[part 1 of 3: package /MICROSAR_SWCS_DEV/Dem_swc/ComponentTypes]
AUTOSAR XML (schema 4-0-3)
package /MICROSAR_SWCS_DEV/Dem_swc/ComponentTypes
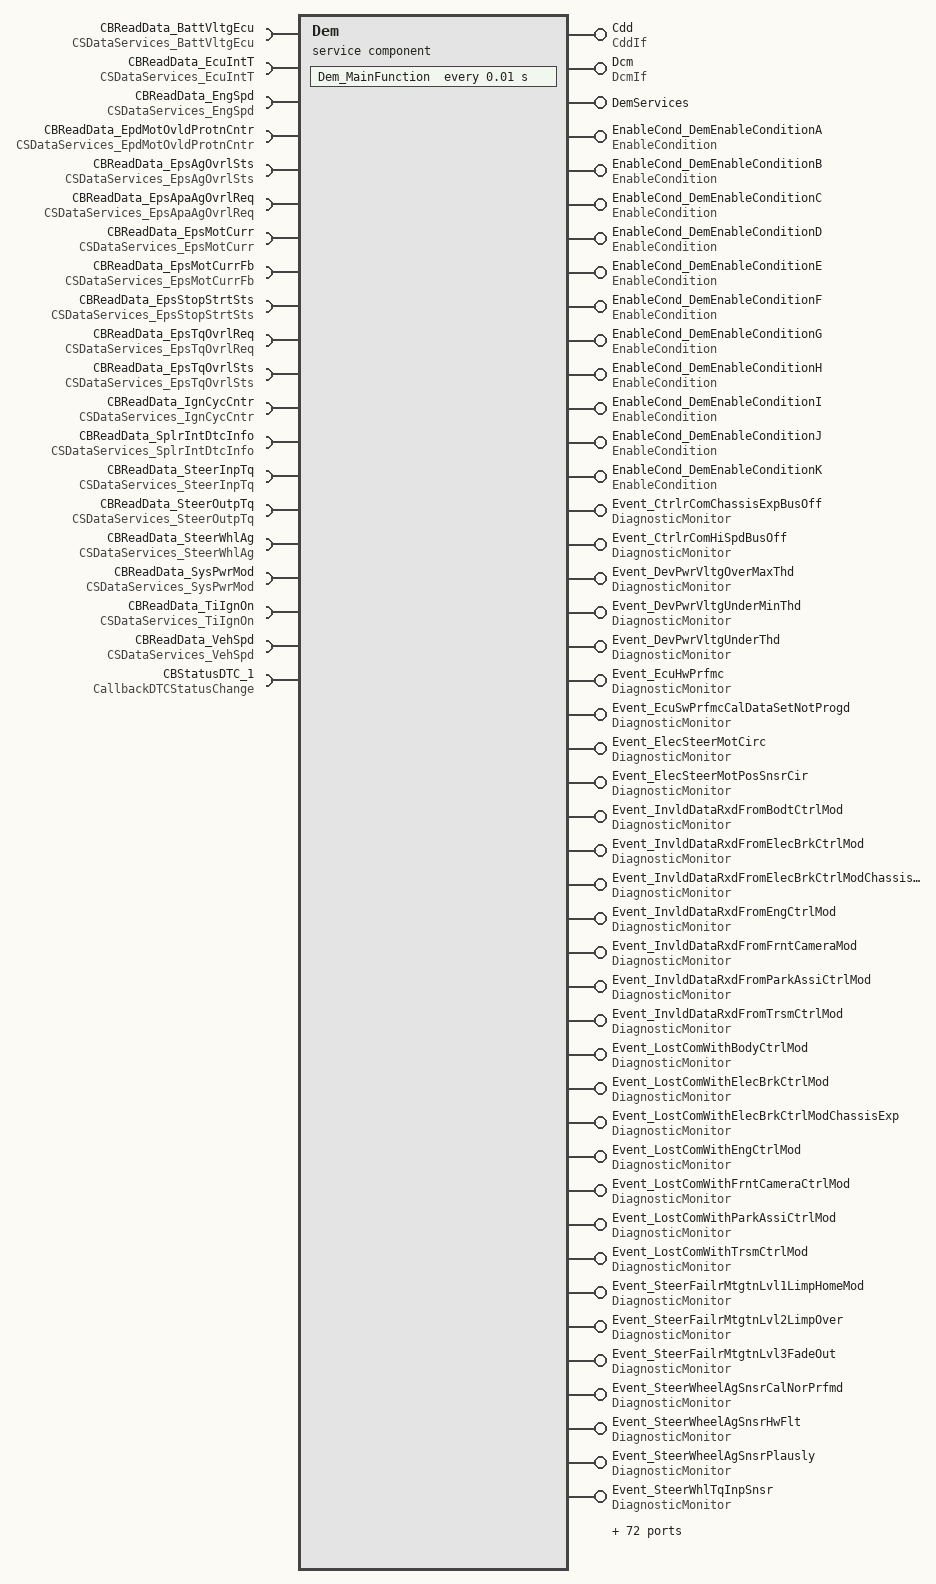
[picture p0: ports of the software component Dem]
  service sw component type Dem
    116 x provide port:
      Cdd: server-com-spec{operation=ClearDTC, queue-length=1}, provided-interface=CddIf
      Dcm: provided-interface=DcmIf
        provided-com-specs:
          operation=DcmClearDTC, queue-length=1
          operation=DcmEnableDTCSetting, queue-length=1
          operation=DcmGetExtendedDataRecordByDTC, queue-length=1
          operation=DcmGetFreezeFrameDataByDTC, queue-length=1
          operation=DcmGetNextFilteredDTCAndFDC, queue-length=1
      DemServices: provided-interface=DemServices
        provided-com-specs:
          operation=GetDTCStatusAvailabilityMask, queue-length=1
          operation=GetPostRunRequested, queue-length=1
      EnableCond_DemEnableConditionA: server-com-spec{operation=SetEnableCondition, queue-length=1}, provided-interface=EnableCondition
      EnableCond_DemEnableConditionB: server-com-spec{operation=SetEnableCondition, queue-length=1}, provided-interface=EnableCondition
      EnableCond_DemEnableConditionC: server-com-spec{operation=SetEnableCondition, queue-length=1}, provided-interface=EnableCondition
      EnableCond_DemEnableConditionD: server-com-spec{operation=SetEnableCondition, queue-length=1}, provided-interface=EnableCondition
      EnableCond_DemEnableConditionE: server-com-spec{operation=SetEnableCondition, queue-length=1}, provided-interface=EnableCondition
      EnableCond_DemEnableConditionF: server-com-spec{operation=SetEnableCondition, queue-length=1}, provided-interface=EnableCondition
      EnableCond_DemEnableConditionG: server-com-spec{operation=SetEnableCondition, queue-length=1}, provided-interface=EnableCondition
      EnableCond_DemEnableConditionH: server-com-spec{operation=SetEnableCondition, queue-length=1}, provided-interface=EnableCondition
      EnableCond_DemEnableConditionI: server-com-spec{operation=SetEnableCondition, queue-length=1}, provided-interface=EnableCondition
      EnableCond_DemEnableConditionJ: server-com-spec{operation=SetEnableCondition, queue-length=1}, provided-interface=EnableCondition
      EnableCond_DemEnableConditionK: server-com-spec{operation=SetEnableCondition, queue-length=1}, provided-interface=EnableCondition
      Event_CtrlrComChassisExpBusOff: provided-interface=DiagnosticMonitor
        provided-com-specs:
          operation=GetDTCOfEvent, queue-length=1
          operation=GetEventExtendedDataRecord, queue-length=1
          operation=GetEventFailed, queue-length=1
          operation=GetEventFreezeFrameData, queue-length=1
          operation=GetEventStatus, queue-length=1
          operation=GetEventTested, queue-length=1
          operation=GetFaultDetectionCounter, queue-length=1
          operation=ResetEventDebounceStatus, queue-length=1
          operation=ResetEventStatus, queue-length=1
          operation=SetEventStatus, queue-length=1
      Event_CtrlrComHiSpdBusOff: provided-interface=DiagnosticMonitor
        provided-com-specs:
          operation=GetDTCOfEvent, queue-length=1
          operation=GetEventExtendedDataRecord, queue-length=1
          operation=GetEventFailed, queue-length=1
          operation=GetEventFreezeFrameData, queue-length=1
          operation=GetEventStatus, queue-length=1
          operation=GetEventTested, queue-length=1
          operation=GetFaultDetectionCounter, queue-length=1
          operation=ResetEventDebounceStatus, queue-length=1
          operation=ResetEventStatus, queue-length=1
          operation=SetEventStatus, queue-length=1
      Event_DevPwrVltgOverMaxThd: provided-interface=DiagnosticMonitor
        provided-com-specs:
          operation=GetDTCOfEvent, queue-length=1
          operation=GetEventExtendedDataRecord, queue-length=1
          operation=GetEventFailed, queue-length=1
          operation=GetEventFreezeFrameData, queue-length=1
          operation=GetEventStatus, queue-length=1
          operation=GetEventTested, queue-length=1
          operation=GetFaultDetectionCounter, queue-length=1
          operation=ResetEventDebounceStatus, queue-length=1
          operation=ResetEventStatus, queue-length=1
          operation=SetEventStatus, queue-length=1
      Event_DevPwrVltgUnderMinThd: provided-interface=DiagnosticMonitor
        provided-com-specs:
          operation=GetDTCOfEvent, queue-length=1
          operation=GetEventExtendedDataRecord, queue-length=1
          operation=GetEventFailed, queue-length=1
          operation=GetEventFreezeFrameData, queue-length=1
          operation=GetEventStatus, queue-length=1
          operation=GetEventTested, queue-length=1
          operation=GetFaultDetectionCounter, queue-length=1
          operation=ResetEventDebounceStatus, queue-length=1
          operation=ResetEventStatus, queue-length=1
          operation=SetEventStatus, queue-length=1
      Event_DevPwrVltgUnderThd: provided-interface=DiagnosticMonitor
        provided-com-specs:
          operation=GetDTCOfEvent, queue-length=1
          operation=GetEventExtendedDataRecord, queue-length=1
          operation=GetEventFailed, queue-length=1
          operation=GetEventFreezeFrameData, queue-length=1
          operation=GetEventStatus, queue-length=1
          operation=GetEventTested, queue-length=1
          operation=GetFaultDetectionCounter, queue-length=1
          operation=ResetEventDebounceStatus, queue-length=1
          operation=ResetEventStatus, queue-length=1
          operation=SetEventStatus, queue-length=1
      Event_EcuHwPrfmc: provided-interface=DiagnosticMonitor
        provided-com-specs:
          operation=GetDTCOfEvent, queue-length=1
          operation=GetEventExtendedDataRecord, queue-length=1
          operation=GetEventFailed, queue-length=1
          operation=GetEventFreezeFrameData, queue-length=1
          operation=GetEventStatus, queue-length=1
          operation=GetEventTested, queue-length=1
          operation=GetFaultDetectionCounter, queue-length=1
          operation=ResetEventDebounceStatus, queue-length=1
          operation=ResetEventStatus, queue-length=1
          operation=SetEventStatus, queue-length=1
      Event_EcuSwPrfmcCalDataSetNotProgd: provided-interface=DiagnosticMonitor
        provided-com-specs:
          operation=GetDTCOfEvent, queue-length=1
          operation=GetEventExtendedDataRecord, queue-length=1
          operation=GetEventFailed, queue-length=1
          operation=GetEventFreezeFrameData, queue-length=1
          operation=GetEventStatus, queue-length=1
          operation=GetEventTested, queue-length=1
          operation=GetFaultDetectionCounter, queue-length=1
          operation=ResetEventDebounceStatus, queue-length=1
          operation=ResetEventStatus, queue-length=1
          operation=SetEventStatus, queue-length=1
      Event_ElecSteerMotCirc: provided-interface=DiagnosticMonitor
        provided-com-specs:
          operation=GetDTCOfEvent, queue-length=1
          operation=GetEventExtendedDataRecord, queue-length=1
          operation=GetEventFailed, queue-length=1
          operation=GetEventFreezeFrameData, queue-length=1
          operation=GetEventStatus, queue-length=1
          operation=GetEventTested, queue-length=1
          operation=GetFaultDetectionCounter, queue-length=1
          operation=ResetEventDebounceStatus, queue-length=1
          operation=ResetEventStatus, queue-length=1
          operation=SetEventStatus, queue-length=1
      Event_ElecSteerMotPosSnsrCir: provided-interface=DiagnosticMonitor
        provided-com-specs:
          operation=GetDTCOfEvent, queue-length=1
          operation=GetEventExtendedDataRecord, queue-length=1
          operation=GetEventFailed, queue-length=1
          operation=GetEventFreezeFrameData, queue-length=1
          operation=GetEventStatus, queue-length=1
          operation=GetEventTested, queue-length=1
          operation=GetFaultDetectionCounter, queue-length=1
          operation=ResetEventDebounceStatus, queue-length=1
          operation=ResetEventStatus, queue-length=1
          operation=SetEventStatus, queue-length=1
      Event_InvldDataRxdFromBodtCtrlMod: provided-interface=DiagnosticMonitor
        provided-com-specs:
          operation=GetDTCOfEvent, queue-length=1
          operation=GetEventExtendedDataRecord, queue-length=1
          operation=GetEventFailed, queue-length=1
          operation=GetEventFreezeFrameData, queue-length=1
          operation=GetEventStatus, queue-length=1
          operation=GetEventTested, queue-length=1
          operation=GetFaultDetectionCounter, queue-length=1
          operation=ResetEventDebounceStatus, queue-length=1
          operation=ResetEventStatus, queue-length=1
          operation=SetEventStatus, queue-length=1
      Event_InvldDataRxdFromElecBrkCtrlMod: provided-interface=DiagnosticMonitor
        provided-com-specs:
          operation=GetDTCOfEvent, queue-length=1
          operation=GetEventExtendedDataRecord, queue-length=1
          operation=GetEventFailed, queue-length=1
          operation=GetEventFreezeFrameData, queue-length=1
          operation=GetEventStatus, queue-length=1
          operation=GetEventTested, queue-length=1
          operation=GetFaultDetectionCounter, queue-length=1
          operation=ResetEventDebounceStatus, queue-length=1
          operation=ResetEventStatus, queue-length=1
          operation=SetEventStatus, queue-length=1
      Event_InvldDataRxdFromElecBrkCtrlModChassisExp: provided-interface=DiagnosticMonitor
        provided-com-specs:
          operation=GetDTCOfEvent, queue-length=1
          operation=GetEventExtendedDataRecord, queue-length=1
          operation=GetEventFailed, queue-length=1
          operation=GetEventFreezeFrameData, queue-length=1
          operation=GetEventStatus, queue-length=1
          operation=GetEventTested, queue-length=1
          operation=GetFaultDetectionCounter, queue-length=1
          operation=ResetEventDebounceStatus, queue-length=1
          operation=ResetEventStatus, queue-length=1
          operation=SetEventStatus, queue-length=1
      Event_InvldDataRxdFromEngCtrlMod: provided-interface=DiagnosticMonitor
        provided-com-specs:
          operation=GetDTCOfEvent, queue-length=1
          operation=GetEventExtendedDataRecord, queue-length=1
          operation=GetEventFailed, queue-length=1
          operation=GetEventFreezeFrameData, queue-length=1
          operation=GetEventStatus, queue-length=1
          operation=GetEventTested, queue-length=1
          operation=GetFaultDetectionCounter, queue-length=1
          operation=ResetEventDebounceStatus, queue-length=1
          operation=ResetEventStatus, queue-length=1
          operation=SetEventStatus, queue-length=1
      Event_InvldDataRxdFromFrntCameraMod: provided-interface=DiagnosticMonitor
        provided-com-specs:
          operation=GetDTCOfEvent, queue-length=1
          operation=GetEventExtendedDataRecord, queue-length=1
          operation=GetEventFailed, queue-length=1
          operation=GetEventFreezeFrameData, queue-length=1
          operation=GetEventStatus, queue-length=1
          operation=GetEventTested, queue-length=1
          operation=GetFaultDetectionCounter, queue-length=1
          operation=ResetEventDebounceStatus, queue-length=1
          operation=ResetEventStatus, queue-length=1
          operation=SetEventStatus, queue-length=1
      Event_InvldDataRxdFromParkAssiCtrlMod: provided-interface=DiagnosticMonitor
        provided-com-specs:
          operation=GetDTCOfEvent, queue-length=1
          operation=GetEventExtendedDataRecord, queue-length=1
          operation=GetEventFailed, queue-length=1
          operation=GetEventFreezeFrameData, queue-length=1
          operation=GetEventStatus, queue-length=1
          operation=GetEventTested, queue-length=1
          operation=GetFaultDetectionCounter, queue-length=1
          operation=ResetEventDebounceStatus, queue-length=1
          operation=ResetEventStatus, queue-length=1
          operation=SetEventStatus, queue-length=1
      Event_InvldDataRxdFromTrsmCtrlMod: provided-interface=DiagnosticMonitor
        provided-com-specs:
          operation=GetDTCOfEvent, queue-length=1
          operation=GetEventExtendedDataRecord, queue-length=1
          operation=GetEventFailed, queue-length=1
          operation=GetEventFreezeFrameData, queue-length=1
          operation=GetEventStatus, queue-length=1
          operation=GetEventTested, queue-length=1
          operation=GetFaultDetectionCounter, queue-length=1
          operation=ResetEventDebounceStatus, queue-length=1
          operation=ResetEventStatus, queue-length=1
          operation=SetEventStatus, queue-length=1
      Event_LostComWithBodyCtrlMod: provided-interface=DiagnosticMonitor
        provided-com-specs:
          operation=GetDTCOfEvent, queue-length=1
          operation=GetEventExtendedDataRecord, queue-length=1
          operation=GetEventFailed, queue-length=1
          operation=GetEventFreezeFrameData, queue-length=1
          operation=GetEventStatus, queue-length=1
          operation=GetEventTested, queue-length=1
          operation=GetFaultDetectionCounter, queue-length=1
          operation=ResetEventDebounceStatus, queue-length=1
          operation=ResetEventStatus, queue-length=1
          operation=SetEventStatus, queue-length=1
      Event_LostComWithElecBrkCtrlMod: provided-interface=DiagnosticMonitor
        provided-com-specs:
          operation=GetDTCOfEvent, queue-length=1
          operation=GetEventExtendedDataRecord, queue-length=1
          operation=GetEventFailed, queue-length=1
          operation=GetEventFreezeFrameData, queue-length=1
          operation=GetEventStatus, queue-length=1
          operation=GetEventTested, queue-length=1
          operation=GetFaultDetectionCounter, queue-length=1
          operation=ResetEventDebounceStatus, queue-length=1
          operation=ResetEventStatus, queue-length=1
          operation=SetEventStatus, queue-length=1
      Event_LostComWithElecBrkCtrlModChassisExp: provided-interface=DiagnosticMonitor
        provided-com-specs:
          operation=GetDTCOfEvent, queue-length=1
          operation=GetEventExtendedDataRecord, queue-length=1
          operation=GetEventFailed, queue-length=1
          operation=GetEventFreezeFrameData, queue-length=1
          operation=GetEventStatus, queue-length=1
          operation=GetEventTested, queue-length=1
          operation=GetFaultDetectionCounter, queue-length=1
          operation=ResetEventDebounceStatus, queue-length=1
          operation=ResetEventStatus, queue-length=1
          operation=SetEventStatus, queue-length=1
      Event_LostComWithEngCtrlMod: provided-interface=DiagnosticMonitor
        provided-com-specs:
          operation=GetDTCOfEvent, queue-length=1
          operation=GetEventExtendedDataRecord, queue-length=1
          operation=GetEventFailed, queue-length=1
          operation=GetEventFreezeFrameData, queue-length=1
          operation=GetEventStatus, queue-length=1
          operation=GetEventTested, queue-length=1
          operation=GetFaultDetectionCounter, queue-length=1
          operation=ResetEventDebounceStatus, queue-length=1
          operation=ResetEventStatus, queue-length=1
          operation=SetEventStatus, queue-length=1
      Event_LostComWithFrntCameraCtrlMod: provided-interface=DiagnosticMonitor
        provided-com-specs:
          operation=GetDTCOfEvent, queue-length=1
          operation=GetEventExtendedDataRecord, queue-length=1
          operation=GetEventFailed, queue-length=1
          operation=GetEventFreezeFrameData, queue-length=1
          operation=GetEventStatus, queue-length=1
          operation=GetEventTested, queue-length=1
          operation=GetFaultDetectionCounter, queue-length=1
          operation=ResetEventDebounceStatus, queue-length=1
          operation=ResetEventStatus, queue-length=1
          operation=SetEventStatus, queue-length=1
      Event_LostComWithParkAssiCtrlMod: provided-interface=DiagnosticMonitor
        provided-com-specs:
          operation=GetDTCOfEvent, queue-length=1
          operation=GetEventExtendedDataRecord, queue-length=1
          operation=GetEventFailed, queue-length=1
          operation=GetEventFreezeFrameData, queue-length=1
          operation=GetEventStatus, queue-length=1
          operation=GetEventTested, queue-length=1
          operation=GetFaultDetectionCounter, queue-length=1
          operation=ResetEventDebounceStatus, queue-length=1
          operation=ResetEventStatus, queue-length=1
          operation=SetEventStatus, queue-length=1
      Event_LostComWithTrsmCtrlMod: provided-interface=DiagnosticMonitor
        provided-com-specs:
          operation=GetDTCOfEvent, queue-length=1
          operation=GetEventExtendedDataRecord, queue-length=1
          operation=GetEventFailed, queue-length=1
          operation=GetEventFreezeFrameData, queue-length=1
          operation=GetEventStatus, queue-length=1
          operation=GetEventTested, queue-length=1
          operation=GetFaultDetectionCounter, queue-length=1
          operation=ResetEventDebounceStatus, queue-length=1
          operation=ResetEventStatus, queue-length=1
          operation=SetEventStatus, queue-length=1
      Event_SteerFailrMtgtnLvl1LimpHomeMod: provided-interface=DiagnosticMonitor
        provided-com-specs:
          operation=GetDTCOfEvent, queue-length=1
          operation=GetEventExtendedDataRecord, queue-length=1
          operation=GetEventFailed, queue-length=1
          operation=GetEventFreezeFrameData, queue-length=1
          operation=GetEventStatus, queue-length=1
          operation=GetEventTested, queue-length=1
          operation=GetFaultDetectionCounter, queue-length=1
          operation=ResetEventDebounceStatus, queue-length=1
          operation=ResetEventStatus, queue-length=1
          operation=SetEventStatus, queue-length=1
      Event_SteerFailrMtgtnLvl2LimpOver: provided-interface=DiagnosticMonitor
        provided-com-specs:
          operation=GetDTCOfEvent, queue-length=1
          operation=GetEventExtendedDataRecord, queue-length=1
          operation=GetEventFailed, queue-length=1
          operation=GetEventFreezeFrameData, queue-length=1
          operation=GetEventStatus, queue-length=1
          operation=GetEventTested, queue-length=1
          operation=GetFaultDetectionCounter, queue-length=1
          operation=ResetEventDebounceStatus, queue-length=1
          operation=ResetEventStatus, queue-length=1
          operation=SetEventStatus, queue-length=1
      Event_SteerFailrMtgtnLvl3FadeOut: provided-interface=DiagnosticMonitor
        provided-com-specs:
          operation=GetDTCOfEvent, queue-length=1
          operation=GetEventExtendedDataRecord, queue-length=1
          operation=GetEventFailed, queue-length=1
          operation=GetEventFreezeFrameData, queue-length=1
          operation=GetEventStatus, queue-length=1
          operation=GetEventTested, queue-length=1
          operation=GetFaultDetectionCounter, queue-length=1
          operation=ResetEventDebounceStatus, queue-length=1
          operation=ResetEventStatus, queue-length=1
          operation=SetEventStatus, queue-length=1
      Event_SteerWheelAgSnsrCalNorPrfmd: provided-interface=DiagnosticMonitor
        provided-com-specs:
          operation=GetDTCOfEvent, queue-length=1
          operation=GetEventExtendedDataRecord, queue-length=1
          operation=GetEventFailed, queue-length=1
          operation=GetEventFreezeFrameData, queue-length=1
          operation=GetEventStatus, queue-length=1
          operation=GetEventTested, queue-length=1
          operation=GetFaultDetectionCounter, queue-length=1
          operation=ResetEventDebounceStatus, queue-length=1
          operation=ResetEventStatus, queue-length=1
          operation=SetEventStatus, queue-length=1
      Event_SteerWheelAgSnsrHwFlt: provided-interface=DiagnosticMonitor
        provided-com-specs:
          operation=GetDTCOfEvent, queue-length=1
          operation=GetEventExtendedDataRecord, queue-length=1
          operation=GetEventFailed, queue-length=1
          operation=GetEventFreezeFrameData, queue-length=1
          operation=GetEventStatus, queue-length=1
          operation=GetEventTested, queue-length=1
          operation=GetFaultDetectionCounter, queue-length=1
          operation=ResetEventDebounceStatus, queue-length=1
          operation=ResetEventStatus, queue-length=1
          operation=SetEventStatus, queue-length=1
      Event_SteerWheelAgSnsrPlausly: provided-interface=DiagnosticMonitor
        provided-com-specs:
          operation=GetDTCOfEvent, queue-length=1
          operation=GetEventExtendedDataRecord, queue-length=1
          operation=GetEventFailed, queue-length=1
          operation=GetEventFreezeFrameData, queue-length=1
          operation=GetEventStatus, queue-length=1
          operation=GetEventTested, queue-length=1
          operation=GetFaultDetectionCounter, queue-length=1
          operation=ResetEventDebounceStatus, queue-length=1
          operation=ResetEventStatus, queue-length=1
          operation=SetEventStatus, queue-length=1
      Event_SteerWhlTqInpSnsr: provided-interface=DiagnosticMonitor
        provided-com-specs:
          operation=GetDTCOfEvent, queue-length=1
          operation=GetEventExtendedDataRecord, queue-length=1
          operation=GetEventFailed, queue-length=1
          operation=GetEventFreezeFrameData, queue-length=1
          operation=GetEventStatus, queue-length=1
          operation=GetEventTested, queue-length=1
          operation=GetFaultDetectionCounter, queue-length=1
          operation=ResetEventDebounceStatus, queue-length=1
          operation=ResetEventStatus, queue-length=1
          operation=SetEventStatus, queue-length=1
      Event_SteerWhlTqInpSnsrCalNoLrnd: provided-interface=DiagnosticMonitor
        provided-com-specs:
          operation=GetDTCOfEvent, queue-length=1
          operation=GetEventExtendedDataRecord, queue-length=1
          operation=GetEventFailed, queue-length=1
          operation=GetEventFreezeFrameData, queue-length=1
          operation=GetEventStatus, queue-length=1
          operation=GetEventTested, queue-length=1
          operation=GetFaultDetectionCounter, queue-length=1
          operation=ResetEventDebounceStatus, queue-length=1
          operation=ResetEventStatus, queue-length=1
          operation=SetEventStatus, queue-length=1
      Event_SysThermErrTHi: provided-interface=DiagnosticMonitor
        provided-com-specs:
          operation=GetDTCOfEvent, queue-length=1
          operation=GetEventExtendedDataRecord, queue-length=1
          operation=GetEventFailed, queue-length=1
          operation=GetEventFreezeFrameData, queue-length=1
          operation=GetEventStatus, queue-length=1
          operation=GetEventTested, queue-length=1
          operation=GetFaultDetectionCounter, queue-length=1
          operation=ResetEventDebounceStatus, queue-length=1
          operation=ResetEventStatus, queue-length=1
          operation=SetEventStatus, queue-length=1
      EvtInfo_CtrlrComChassisExpBusOff: provided-interface=DiagnosticInfo
        provided-com-specs:
          operation=GetDebouncingOfEvent, queue-length=1
          operation=GetDTCOfEvent, queue-length=1
          operation=GetEventEnableCondition, queue-length=1
          operation=GetEventExtendedDataRecord, queue-length=1
          operation=GetEventFailed, queue-length=1
          operation=GetEventFreezeFrameData, queue-length=1
          operation=GetEventStatus, queue-length=1
          operation=GetEventTested, queue-length=1
          operation=GetFaultDetectionCounter, queue-length=1
      EvtInfo_CtrlrComHiSpdBusOff: provided-interface=DiagnosticInfo
        provided-com-specs:
          operation=GetDebouncingOfEvent, queue-length=1
          operation=GetDTCOfEvent, queue-length=1
          operation=GetEventEnableCondition, queue-length=1
          operation=GetEventExtendedDataRecord, queue-length=1
          operation=GetEventFailed, queue-length=1
          operation=GetEventFreezeFrameData, queue-length=1
          operation=GetEventStatus, queue-length=1
          operation=GetEventTested, queue-length=1
          operation=GetFaultDetectionCounter, queue-length=1
      EvtInfo_DevPwrVltgOverMaxThd: provided-interface=DiagnosticInfo
        provided-com-specs:
          operation=GetDebouncingOfEvent, queue-length=1
          operation=GetDTCOfEvent, queue-length=1
          operation=GetEventEnableCondition, queue-length=1
          operation=GetEventExtendedDataRecord, queue-length=1
          operation=GetEventFailed, queue-length=1
          operation=GetEventFreezeFrameData, queue-length=1
          operation=GetEventStatus, queue-length=1
          operation=GetEventTested, queue-length=1
          operation=GetFaultDetectionCounter, queue-length=1
      EvtInfo_DevPwrVltgUnderMinThd: provided-interface=DiagnosticInfo
        provided-com-specs:
          operation=GetDebouncingOfEvent, queue-length=1
          operation=GetDTCOfEvent, queue-length=1
          operation=GetEventEnableCondition, queue-length=1
          operation=GetEventExtendedDataRecord, queue-length=1
          operation=GetEventFailed, queue-length=1
          operation=GetEventFreezeFrameData, queue-length=1
          operation=GetEventStatus, queue-length=1
          operation=GetEventTested, queue-length=1
          operation=GetFaultDetectionCounter, queue-length=1
      EvtInfo_DevPwrVltgUnderThd: provided-interface=DiagnosticInfo
        provided-com-specs:
          operation=GetDebouncingOfEvent, queue-length=1
          operation=GetDTCOfEvent, queue-length=1
          operation=GetEventEnableCondition, queue-length=1
          operation=GetEventExtendedDataRecord, queue-length=1
          operation=GetEventFailed, queue-length=1
          operation=GetEventFreezeFrameData, queue-length=1
          operation=GetEventStatus, queue-length=1
          operation=GetEventTested, queue-length=1
          operation=GetFaultDetectionCounter, queue-length=1
      EvtInfo_DIO_E_REG_WRITE_VERIFY: provided-interface=DiagnosticInfo
        provided-com-specs:
          operation=GetDebouncingOfEvent, queue-length=1
          operation=GetDTCOfEvent, queue-length=1
          operation=GetEventEnableCondition, queue-length=1
          operation=GetEventExtendedDataRecord, queue-length=1
          operation=GetEventFailed, queue-length=1
          operation=GetEventFreezeFrameData, queue-length=1
          operation=GetEventStatus, queue-length=1
          operation=GetEventTested, queue-length=1
          operation=GetFaultDetectionCounter, queue-length=1
      EvtInfo_EcuHwPrfmc: provided-interface=DiagnosticInfo
        provided-com-specs:
          operation=GetDebouncingOfEvent, queue-length=1
          operation=GetDTCOfEvent, queue-length=1
          operation=GetEventEnableCondition, queue-length=1
          operation=GetEventExtendedDataRecord, queue-length=1
          operation=GetEventFailed, queue-length=1
          operation=GetEventFreezeFrameData, queue-length=1
          operation=GetEventStatus, queue-length=1
          operation=GetEventTested, queue-length=1
          operation=GetFaultDetectionCounter, queue-length=1
      EvtInfo_EcuSwPrfmcCalDataSetNotProgd: provided-interface=DiagnosticInfo
        provided-com-specs:
          operation=GetDebouncingOfEvent, queue-length=1
          operation=GetDTCOfEvent, queue-length=1
          operation=GetEventEnableCondition, queue-length=1
          operation=GetEventExtendedDataRecord, queue-length=1
          operation=GetEventFailed, queue-length=1
          operation=GetEventFreezeFrameData, queue-length=1
          operation=GetEventStatus, queue-length=1
          operation=GetEventTested, queue-length=1
          operation=GetFaultDetectionCounter, queue-length=1
      EvtInfo_ElecSteerMotCirc: provided-interface=DiagnosticInfo
        provided-com-specs:
          operation=GetDebouncingOfEvent, queue-length=1
          operation=GetDTCOfEvent, queue-length=1
          operation=GetEventEnableCondition, queue-length=1
          operation=GetEventExtendedDataRecord, queue-length=1
          operation=GetEventFailed, queue-length=1
          operation=GetEventFreezeFrameData, queue-length=1
          operation=GetEventStatus, queue-length=1
          operation=GetEventTested, queue-length=1
          operation=GetFaultDetectionCounter, queue-length=1
      EvtInfo_ElecSteerMotPosSnsrCir: provided-interface=DiagnosticInfo
        provided-com-specs:
          operation=GetDebouncingOfEvent, queue-length=1
          operation=GetDTCOfEvent, queue-length=1
          operation=GetEventEnableCondition, queue-length=1
          operation=GetEventExtendedDataRecord, queue-length=1
          operation=GetEventFailed, queue-length=1
          operation=GetEventFreezeFrameData, queue-length=1
          operation=GetEventStatus, queue-length=1
          operation=GetEventTested, queue-length=1
          operation=GetFaultDetectionCounter, queue-length=1
      EvtInfo_FLS_E_COMPARE_FAILED: provided-interface=DiagnosticInfo
        provided-com-specs:
          operation=GetDebouncingOfEvent, queue-length=1
          operation=GetDTCOfEvent, queue-length=1
          operation=GetEventEnableCondition, queue-length=1
          operation=GetEventExtendedDataRecord, queue-length=1
          operation=GetEventFailed, queue-length=1
          operation=GetEventFreezeFrameData, queue-length=1
          operation=GetEventStatus, queue-length=1
          operation=GetEventTested, queue-length=1
          operation=GetFaultDetectionCounter, queue-length=1
      EvtInfo_FLS_E_ERASE_FAILED: provided-interface=DiagnosticInfo
        provided-com-specs:
          operation=GetDebouncingOfEvent, queue-length=1
          operation=GetDTCOfEvent, queue-length=1
          operation=GetEventEnableCondition, queue-length=1
          operation=GetEventExtendedDataRecord, queue-length=1
          operation=GetEventFailed, queue-length=1
          operation=GetEventFreezeFrameData, queue-length=1
          operation=GetEventStatus, queue-length=1
          operation=GetEventTested, queue-length=1
          operation=GetFaultDetectionCounter, queue-length=1
      EvtInfo_FLS_E_READ_FAILED: provided-interface=DiagnosticInfo
        provided-com-specs:
          operation=GetDebouncingOfEvent, queue-length=1
          operation=GetDTCOfEvent, queue-length=1
          operation=GetEventEnableCondition, queue-length=1
          operation=GetEventExtendedDataRecord, queue-length=1
          operation=GetEventFailed, queue-length=1
          operation=GetEventFreezeFrameData, queue-length=1
          operation=GetEventStatus, queue-length=1
          operation=GetEventTested, queue-length=1
          operation=GetFaultDetectionCounter, queue-length=1
      EvtInfo_FLS_E_READ_FAILED_DED: provided-interface=DiagnosticInfo
        provided-com-specs:
          operation=GetDebouncingOfEvent, queue-length=1
          operation=GetDTCOfEvent, queue-length=1
          operation=GetEventEnableCondition, queue-length=1
          operation=GetEventExtendedDataRecord, queue-length=1
          operation=GetEventFailed, queue-length=1
          operation=GetEventFreezeFrameData, queue-length=1
          operation=GetEventStatus, queue-length=1
          operation=GetEventTested, queue-length=1
          operation=GetFaultDetectionCounter, queue-length=1
      EvtInfo_FLS_E_WRITE_FAILED: provided-interface=DiagnosticInfo
        provided-com-specs:
          operation=GetDebouncingOfEvent, queue-length=1
          operation=GetDTCOfEvent, queue-length=1
          operation=GetEventEnableCondition, queue-length=1
          operation=GetEventExtendedDataRecord, queue-length=1
          operation=GetEventFailed, queue-length=1
          operation=GetEventFreezeFrameData, queue-length=1
          operation=GetEventStatus, queue-length=1
          operation=GetEventTested, queue-length=1
          operation=GetFaultDetectionCounter, queue-length=1
      EvtInfo_InvldDataRxdFromBodtCtrlMod: provided-interface=DiagnosticInfo
        provided-com-specs:
          operation=GetDebouncingOfEvent, queue-length=1
          operation=GetDTCOfEvent, queue-length=1
          operation=GetEventEnableCondition, queue-length=1
          operation=GetEventExtendedDataRecord, queue-length=1
          operation=GetEventFailed, queue-length=1
          operation=GetEventFreezeFrameData, queue-length=1
          operation=GetEventStatus, queue-length=1
          operation=GetEventTested, queue-length=1
          operation=GetFaultDetectionCounter, queue-length=1
      EvtInfo_InvldDataRxdFromElecBrkCtrlMod: provided-interface=DiagnosticInfo
        provided-com-specs:
          operation=GetDebouncingOfEvent, queue-length=1
          operation=GetDTCOfEvent, queue-length=1
          operation=GetEventEnableCondition, queue-length=1
          operation=GetEventExtendedDataRecord, queue-length=1
          operation=GetEventFailed, queue-length=1
          operation=GetEventFreezeFrameData, queue-length=1
          operation=GetEventStatus, queue-length=1
          operation=GetEventTested, queue-length=1
          operation=GetFaultDetectionCounter, queue-length=1
      EvtInfo_InvldDataRxdFromElecBrkCtrlModChassisExp: provided-interface=DiagnosticInfo
        provided-com-specs:
          operation=GetDebouncingOfEvent, queue-length=1
          operation=GetDTCOfEvent, queue-length=1
          operation=GetEventEnableCondition, queue-length=1
          operation=GetEventExtendedDataRecord, queue-length=1
          operation=GetEventFailed, queue-length=1
          operation=GetEventFreezeFrameData, queue-length=1
          operation=GetEventStatus, queue-length=1
          operation=GetEventTested, queue-length=1
          operation=GetFaultDetectionCounter, queue-length=1
      EvtInfo_InvldDataRxdFromEngCtrlMod: provided-interface=DiagnosticInfo
        provided-com-specs:
          operation=GetDebouncingOfEvent, queue-length=1
          operation=GetDTCOfEvent, queue-length=1
          operation=GetEventEnableCondition, queue-length=1
          operation=GetEventExtendedDataRecord, queue-length=1
          operation=GetEventFailed, queue-length=1
          operation=GetEventFreezeFrameData, queue-length=1
          operation=GetEventStatus, queue-length=1
          operation=GetEventTested, queue-length=1
          operation=GetFaultDetectionCounter, queue-length=1
      EvtInfo_InvldDataRxdFromFrntCameraMod: provided-interface=DiagnosticInfo
        provided-com-specs:
          operation=GetDebouncingOfEvent, queue-length=1
          operation=GetDTCOfEvent, queue-length=1
          operation=GetEventEnableCondition, queue-length=1
          operation=GetEventExtendedDataRecord, queue-length=1
          operation=GetEventFailed, queue-length=1
          operation=GetEventFreezeFrameData, queue-length=1
          operation=GetEventStatus, queue-length=1
          operation=GetEventTested, queue-length=1
          operation=GetFaultDetectionCounter, queue-length=1
      EvtInfo_InvldDataRxdFromParkAssiCtrlMod: provided-interface=DiagnosticInfo
        provided-com-specs:
          operation=GetDebouncingOfEvent, queue-length=1
          operation=GetDTCOfEvent, queue-length=1
          operation=GetEventEnableCondition, queue-length=1
          operation=GetEventExtendedDataRecord, queue-length=1
          operation=GetEventFailed, queue-length=1
          operation=GetEventFreezeFrameData, queue-length=1
          operation=GetEventStatus, queue-length=1
          operation=GetEventTested, queue-length=1
          operation=GetFaultDetectionCounter, queue-length=1
      EvtInfo_InvldDataRxdFromTrsmCtrlMod: provided-interface=DiagnosticInfo
        provided-com-specs:
          operation=GetDebouncingOfEvent, queue-length=1
          operation=GetDTCOfEvent, queue-length=1
          operation=GetEventEnableCondition, queue-length=1
          operation=GetEventExtendedDataRecord, queue-length=1
          operation=GetEventFailed, queue-length=1
          operation=GetEventFreezeFrameData, queue-length=1
          operation=GetEventStatus, queue-length=1
          operation=GetEventTested, queue-length=1
          operation=GetFaultDetectionCounter, queue-length=1
      EvtInfo_LostComWithBodyCtrlMod: provided-interface=DiagnosticInfo
        provided-com-specs:
          operation=GetDebouncingOfEvent, queue-length=1
          operation=GetDTCOfEvent, queue-length=1
          operation=GetEventEnableCondition, queue-length=1
          operation=GetEventExtendedDataRecord, queue-length=1
          operation=GetEventFailed, queue-length=1
          operation=GetEventFreezeFrameData, queue-length=1
          operation=GetEventStatus, queue-length=1
          operation=GetEventTested, queue-length=1
          operation=GetFaultDetectionCounter, queue-length=1
      EvtInfo_LostComWithElecBrkCtrlMod: provided-interface=DiagnosticInfo
        provided-com-specs:
          operation=GetDebouncingOfEvent, queue-length=1
          operation=GetDTCOfEvent, queue-length=1
          operation=GetEventEnableCondition, queue-length=1
          operation=GetEventExtendedDataRecord, queue-length=1
          operation=GetEventFailed, queue-length=1
          operation=GetEventFreezeFrameData, queue-length=1
          operation=GetEventStatus, queue-length=1
          operation=GetEventTested, queue-length=1
          operation=GetFaultDetectionCounter, queue-length=1
      EvtInfo_LostComWithElecBrkCtrlModChassisExp: provided-interface=DiagnosticInfo
        provided-com-specs:
          operation=GetDebouncingOfEvent, queue-length=1
          operation=GetDTCOfEvent, queue-length=1
          operation=GetEventEnableCondition, queue-length=1
          operation=GetEventExtendedDataRecord, queue-length=1
          operation=GetEventFailed, queue-length=1
          operation=GetEventFreezeFrameData, queue-length=1
          operation=GetEventStatus, queue-length=1
          operation=GetEventTested, queue-length=1
          operation=GetFaultDetectionCounter, queue-length=1
      EvtInfo_LostComWithEngCtrlMod: provided-interface=DiagnosticInfo
        provided-com-specs:
          operation=GetDebouncingOfEvent, queue-length=1
          operation=GetDTCOfEvent, queue-length=1
          operation=GetEventEnableCondition, queue-length=1
          operation=GetEventExtendedDataRecord, queue-length=1
          operation=GetEventFailed, queue-length=1
          operation=GetEventFreezeFrameData, queue-length=1
          operation=GetEventStatus, queue-length=1
          operation=GetEventTested, queue-length=1
          operation=GetFaultDetectionCounter, queue-length=1
      EvtInfo_LostComWithFrntCameraCtrlMod: provided-interface=DiagnosticInfo
        provided-com-specs:
          operation=GetDebouncingOfEvent, queue-length=1
          operation=GetDTCOfEvent, queue-length=1
          operation=GetEventEnableCondition, queue-length=1
          operation=GetEventExtendedDataRecord, queue-length=1
          operation=GetEventFailed, queue-length=1
          operation=GetEventFreezeFrameData, queue-length=1
          operation=GetEventStatus, queue-length=1
          operation=GetEventTested, queue-length=1
          operation=GetFaultDetectionCounter, queue-length=1
      EvtInfo_LostComWithParkAssiCtrlMod: provided-interface=DiagnosticInfo
        provided-com-specs:
          operation=GetDebouncingOfEvent, queue-length=1
          operation=GetDTCOfEvent, queue-length=1
          operation=GetEventEnableCondition, queue-length=1
          operation=GetEventExtendedDataRecord, queue-length=1
          operation=GetEventFailed, queue-length=1
          operation=GetEventFreezeFrameData, queue-length=1
          operation=GetEventStatus, queue-length=1
          operation=GetEventTested, queue-length=1
          operation=GetFaultDetectionCounter, queue-length=1
      EvtInfo_LostComWithTrsmCtrlMod: provided-interface=DiagnosticInfo
        provided-com-specs:
          operation=GetDebouncingOfEvent, queue-length=1
          operation=GetDTCOfEvent, queue-length=1
          operation=GetEventEnableCondition, queue-length=1
          operation=GetEventExtendedDataRecord, queue-length=1
          operation=GetEventFailed, queue-length=1
          operation=GetEventFreezeFrameData, queue-length=1
          operation=GetEventStatus, queue-length=1
          operation=GetEventTested, queue-length=1
          operation=GetFaultDetectionCounter, queue-length=1
      EvtInfo_MCU_E_CLM_SELFDIAG_FAILURE: provided-interface=DiagnosticInfo
        provided-com-specs:
          operation=GetDebouncingOfEvent, queue-length=1
          operation=GetDTCOfEvent, queue-length=1
          operation=GetEventEnableCondition, queue-length=1
          operation=GetEventExtendedDataRecord, queue-length=1
          operation=GetEventFailed, queue-length=1
          operation=GetEventFreezeFrameData, queue-length=1
          operation=GetEventStatus, queue-length=1
          operation=GetEventTested, queue-length=1
          operation=GetFaultDetectionCounter, queue-length=1
      EvtInfo_MCU_E_CLOCK_FAILURE: provided-interface=DiagnosticInfo
        provided-com-specs:
          operation=GetDebouncingOfEvent, queue-length=1
          operation=GetDTCOfEvent, queue-length=1
          operation=GetEventEnableCondition, queue-length=1
          operation=GetEventExtendedDataRecord, queue-length=1
          operation=GetEventFailed, queue-length=1
          operation=GetEventFreezeFrameData, queue-length=1
          operation=GetEventStatus, queue-length=1
          operation=GetEventTested, queue-length=1
          operation=GetFaultDetectionCounter, queue-length=1
      EvtInfo_MCU_E_CVM_SELFDIAG_FAILURE: provided-interface=DiagnosticInfo
        provided-com-specs:
          operation=GetDebouncingOfEvent, queue-length=1
          operation=GetDTCOfEvent, queue-length=1
          operation=GetEventEnableCondition, queue-length=1
          operation=GetEventExtendedDataRecord, queue-length=1
          operation=GetEventFailed, queue-length=1
          operation=GetEventFreezeFrameData, queue-length=1
          operation=GetEventStatus, queue-length=1
          operation=GetEventTested, queue-length=1
          operation=GetFaultDetectionCounter, queue-length=1
      EvtInfo_MCU_E_ECM_SELFDIAG_FAILURE: provided-interface=DiagnosticInfo
        provided-com-specs:
          operation=GetDebouncingOfEvent, queue-length=1
          operation=GetDTCOfEvent, queue-length=1
          operation=GetEventEnableCondition, queue-length=1
          operation=GetEventExtendedDataRecord, queue-length=1
          operation=GetEventFailed, queue-length=1
          operation=GetEventFreezeFrameData, queue-length=1
          operation=GetEventStatus, queue-length=1
          operation=GetEventTested, queue-length=1
          operation=GetFaultDetectionCounter, queue-length=1
      EvtInfo_MCU_E_INT_INCONSISTENT: provided-interface=DiagnosticInfo
        provided-com-specs:
          operation=GetDebouncingOfEvent, queue-length=1
          operation=GetDTCOfEvent, queue-length=1
          operation=GetEventEnableCondition, queue-length=1
          operation=GetEventExtendedDataRecord, queue-length=1
          operation=GetEventFailed, queue-length=1
          operation=GetEventFreezeFrameData, queue-length=1
          operation=GetEventStatus, queue-length=1
          operation=GetEventTested, queue-length=1
          operation=GetFaultDetectionCounter, queue-length=1
      EvtInfo_MCU_E_LOCKSTEP_SELFDIAG_FAILURE: provided-interface=DiagnosticInfo
        provided-com-specs:
          operation=GetDebouncingOfEvent, queue-length=1
          operation=GetDTCOfEvent, queue-length=1
          operation=GetEventEnableCondition, queue-length=1
          operation=GetEventExtendedDataRecord, queue-length=1
          operation=GetEventFailed, queue-length=1
          operation=GetEventFreezeFrameData, queue-length=1
          operation=GetEventStatus, queue-length=1
          operation=GetEventTested, queue-length=1
          operation=GetFaultDetectionCounter, queue-length=1
      EvtInfo_MCU_E_REG_WRITE_VERIFY: provided-interface=DiagnosticInfo
        provided-com-specs:
          operation=GetDebouncingOfEvent, queue-length=1
          operation=GetDTCOfEvent, queue-length=1
          operation=GetEventEnableCondition, queue-length=1
          operation=GetEventExtendedDataRecord, queue-length=1
          operation=GetEventFailed, queue-length=1
          operation=GetEventFreezeFrameData, queue-length=1
          operation=GetEventStatus, queue-length=1
          operation=GetEventTested, queue-length=1
          operation=GetFaultDetectionCounter, queue-length=1
      EvtInfo_MCU_E_WRITE_TIMEOUT_FAILURE: provided-interface=DiagnosticInfo
        provided-com-specs:
          operation=GetDebouncingOfEvent, queue-length=1
          operation=GetDTCOfEvent, queue-length=1
          operation=GetEventEnableCondition, queue-length=1
          operation=GetEventExtendedDataRecord, queue-length=1
          operation=GetEventFailed, queue-length=1
          operation=GetEventFreezeFrameData, queue-length=1
          operation=GetEventStatus, queue-length=1
          operation=GetEventTested, queue-length=1
          operation=GetFaultDetectionCounter, queue-length=1
      EvtInfo_NVM_E_INTEGRITY_FAILED: provided-interface=DiagnosticInfo
        provided-com-specs:
          operation=GetDebouncingOfEvent, queue-length=1
          operation=GetDTCOfEvent, queue-length=1
          operation=GetEventEnableCondition, queue-length=1
          operation=GetEventExtendedDataRecord, queue-length=1
          operation=GetEventFailed, queue-length=1
          operation=GetEventFreezeFrameData, queue-length=1
          operation=GetEventStatus, queue-length=1
          operation=GetEventTested, queue-length=1
          operation=GetFaultDetectionCounter, queue-length=1
      EvtInfo_NVM_E_LOSS_OF_REDUNDANCY: provided-interface=DiagnosticInfo
        provided-com-specs:
          operation=GetDebouncingOfEvent, queue-length=1
          operation=GetDTCOfEvent, queue-length=1
          operation=GetEventEnableCondition, queue-length=1
          operation=GetEventExtendedDataRecord, queue-length=1
          operation=GetEventFailed, queue-length=1
          operation=GetEventFreezeFrameData, queue-length=1
          operation=GetEventStatus, queue-length=1
          operation=GetEventTested, queue-length=1
          operation=GetFaultDetectionCounter, queue-length=1
      EvtInfo_NVM_E_QUEUE_OVERFLOW: provided-interface=DiagnosticInfo
        provided-com-specs:
          operation=GetDebouncingOfEvent, queue-length=1
          operation=GetDTCOfEvent, queue-length=1
          operation=GetEventEnableCondition, queue-length=1
          operation=GetEventExtendedDataRecord, queue-length=1
          operation=GetEventFailed, queue-length=1
          operation=GetEventFreezeFrameData, queue-length=1
          operation=GetEventStatus, queue-length=1
          operation=GetEventTested, queue-length=1
          operation=GetFaultDetectionCounter, queue-length=1
      EvtInfo_NVM_E_REQ_FAILED: provided-interface=DiagnosticInfo
        provided-com-specs:
          operation=GetDebouncingOfEvent, queue-length=1
          operation=GetDTCOfEvent, queue-length=1
          operation=GetEventEnableCondition, queue-length=1
          operation=GetEventExtendedDataRecord, queue-length=1
          operation=GetEventFailed, queue-length=1
          operation=GetEventFreezeFrameData, queue-length=1
          operation=GetEventStatus, queue-length=1
          operation=GetEventTested, queue-length=1
          operation=GetFaultDetectionCounter, queue-length=1
      EvtInfo_NVM_E_VERIFY_FAILED: provided-interface=DiagnosticInfo
        provided-com-specs:
          operation=GetDebouncingOfEvent, queue-length=1
          operation=GetDTCOfEvent, queue-length=1
          operation=GetEventEnableCondition, queue-length=1
          operation=GetEventExtendedDataRecord, queue-length=1
          operation=GetEventFailed, queue-length=1
          operation=GetEventFreezeFrameData, queue-length=1
          operation=GetEventStatus, queue-length=1
          operation=GetEventTested, queue-length=1
          operation=GetFaultDetectionCounter, queue-length=1
      EvtInfo_NVM_E_WRITE_PROTECTED: provided-interface=DiagnosticInfo
        provided-com-specs:
          operation=GetDebouncingOfEvent, queue-length=1
          operation=GetDTCOfEvent, queue-length=1
          operation=GetEventEnableCondition, queue-length=1
          operation=GetEventExtendedDataRecord, queue-length=1
          operation=GetEventFailed, queue-length=1
          operation=GetEventFreezeFrameData, queue-length=1
          operation=GetEventStatus, queue-length=1
          operation=GetEventTested, queue-length=1
          operation=GetFaultDetectionCounter, queue-length=1
      EvtInfo_NVM_E_WRONG_BLOCK_ID: provided-interface=DiagnosticInfo
        provided-com-specs:
          operation=GetDebouncingOfEvent, queue-length=1
          operation=GetDTCOfEvent, queue-length=1
          operation=GetEventEnableCondition, queue-length=1
          operation=GetEventExtendedDataRecord, queue-length=1
          operation=GetEventFailed, queue-length=1
          operation=GetEventFreezeFrameData, queue-length=1
          operation=GetEventStatus, queue-length=1
          operation=GetEventTested, queue-length=1
          operation=GetFaultDetectionCounter, queue-length=1
      EvtInfo_PORT_E_REG_WRITE_VERIFY: provided-interface=DiagnosticInfo
        provided-com-specs:
          operation=GetDebouncingOfEvent, queue-length=1
          operation=GetDTCOfEvent, queue-length=1
          operation=GetEventEnableCondition, queue-length=1
          operation=GetEventExtendedDataRecord, queue-length=1
          operation=GetEventFailed, queue-length=1
          operation=GetEventFreezeFrameData, queue-length=1
          operation=GetEventStatus, queue-length=1
          operation=GetEventTested, queue-length=1
          operation=GetFaultDetectionCounter, queue-length=1
      EvtInfo_PORT_E_WRITE_TIMEOUT_FAILURE: provided-interface=DiagnosticInfo
        provided-com-specs:
          operation=GetDebouncingOfEvent, queue-length=1
          operation=GetDTCOfEvent, queue-length=1
          operation=GetEventEnableCondition, queue-length=1
          operation=GetEventExtendedDataRecord, queue-length=1
          operation=GetEventFailed, queue-length=1
          operation=GetEventFreezeFrameData, queue-length=1
          operation=GetEventStatus, queue-length=1
          operation=GetEventTested, queue-length=1
          operation=GetFaultDetectionCounter, queue-length=1
      EvtInfo_SPI_E_DATA_TX_TIMEOUT_FAILURE: provided-interface=DiagnosticInfo
        provided-com-specs:
          operation=GetDebouncingOfEvent, queue-length=1
          operation=GetDTCOfEvent, queue-length=1
          operation=GetEventEnableCondition, queue-length=1
          operation=GetEventExtendedDataRecord, queue-length=1
          operation=GetEventFailed, queue-length=1
          operation=GetEventFreezeFrameData, queue-length=1
          operation=GetEventStatus, queue-length=1
          operation=GetEventTested, queue-length=1
          operation=GetFaultDetectionCounter, queue-length=1
      EvtInfo_SPI_E_HARDWARE_ERROR: provided-interface=DiagnosticInfo
        provided-com-specs:
          operation=GetDebouncingOfEvent, queue-length=1
          operation=GetDTCOfEvent, queue-length=1
          operation=GetEventEnableCondition, queue-length=1
          operation=GetEventExtendedDataRecord, queue-length=1
          operation=GetEventFailed, queue-length=1
          operation=GetEventFreezeFrameData, queue-length=1
          operation=GetEventStatus, queue-length=1
          operation=GetEventTested, queue-length=1
          operation=GetFaultDetectionCounter, queue-length=1
      EvtInfo_SteerFailrMtgtnLvl1LimpHomeMod: provided-interface=DiagnosticInfo
        provided-com-specs:
          operation=GetDebouncingOfEvent, queue-length=1
          operation=GetDTCOfEvent, queue-length=1
          operation=GetEventEnableCondition, queue-length=1
          operation=GetEventExtendedDataRecord, queue-length=1
          operation=GetEventFailed, queue-length=1
          operation=GetEventFreezeFrameData, queue-length=1
          operation=GetEventStatus, queue-length=1
          operation=GetEventTested, queue-length=1
          operation=GetFaultDetectionCounter, queue-length=1
      EvtInfo_SteerFailrMtgtnLvl2LimpOver: provided-interface=DiagnosticInfo
        provided-com-specs:
          operation=GetDebouncingOfEvent, queue-length=1
          operation=GetDTCOfEvent, queue-length=1
          operation=GetEventEnableCondition, queue-length=1
          operation=GetEventExtendedDataRecord, queue-length=1
          operation=GetEventFailed, queue-length=1
          operation=GetEventFreezeFrameData, queue-length=1
          operation=GetEventStatus, queue-length=1
          operation=GetEventTested, queue-length=1
          operation=GetFaultDetectionCounter, queue-length=1
      EvtInfo_SteerFailrMtgtnLvl3FadeOut: provided-interface=DiagnosticInfo
        provided-com-specs:
          operation=GetDebouncingOfEvent, queue-length=1
          operation=GetDTCOfEvent, queue-length=1
          operation=GetEventEnableCondition, queue-length=1
          operation=GetEventExtendedDataRecord, queue-length=1
          operation=GetEventFailed, queue-length=1
          operation=GetEventFreezeFrameData, queue-length=1
          operation=GetEventStatus, queue-length=1
          operation=GetEventTested, queue-length=1
          operation=GetFaultDetectionCounter, queue-length=1
      EvtInfo_SteerWheelAgSnsrCalNorPrfmd: provided-interface=DiagnosticInfo
        provided-com-specs:
          operation=GetDebouncingOfEvent, queue-length=1
          operation=GetDTCOfEvent, queue-length=1
          operation=GetEventEnableCondition, queue-length=1
          operation=GetEventExtendedDataRecord, queue-length=1
          operation=GetEventFailed, queue-length=1
          operation=GetEventFreezeFrameData, queue-length=1
          operation=GetEventStatus, queue-length=1
          operation=GetEventTested, queue-length=1
          operation=GetFaultDetectionCounter, queue-length=1
      EvtInfo_SteerWheelAgSnsrHwFlt: provided-interface=DiagnosticInfo
        provided-com-specs:
          operation=GetDebouncingOfEvent, queue-length=1
          operation=GetDTCOfEvent, queue-length=1
          operation=GetEventEnableCondition, queue-length=1
          operation=GetEventExtendedDataRecord, queue-length=1
          operation=GetEventFailed, queue-length=1
          operation=GetEventFreezeFrameData, queue-length=1
          operation=GetEventStatus, queue-length=1
          operation=GetEventTested, queue-length=1
          operation=GetFaultDetectionCounter, queue-length=1
      EvtInfo_SteerWheelAgSnsrPlausly: provided-interface=DiagnosticInfo
        provided-com-specs:
          operation=GetDebouncingOfEvent, queue-length=1
          operation=GetDTCOfEvent, queue-length=1
          operation=GetEventEnableCondition, queue-length=1
          operation=GetEventExtendedDataRecord, queue-length=1
          operation=GetEventFailed, queue-length=1
          operation=GetEventFreezeFrameData, queue-length=1
          operation=GetEventStatus, queue-length=1
          operation=GetEventTested, queue-length=1
          operation=GetFaultDetectionCounter, queue-length=1
      EvtInfo_SteerWhlTqInpSnsr: provided-interface=DiagnosticInfo
        provided-com-specs:
          operation=GetDebouncingOfEvent, queue-length=1
          operation=GetDTCOfEvent, queue-length=1
          operation=GetEventEnableCondition, queue-length=1
          operation=GetEventExtendedDataRecord, queue-length=1
          operation=GetEventFailed, queue-length=1
          operation=GetEventFreezeFrameData, queue-length=1
          operation=GetEventStatus, queue-length=1
          operation=GetEventTested, queue-length=1
          operation=GetFaultDetectionCounter, queue-length=1
      EvtInfo_SteerWhlTqInpSnsrCalNoLrnd: provided-interface=DiagnosticInfo
        provided-com-specs:
          operation=GetDebouncingOfEvent, queue-length=1
          operation=GetDTCOfEvent, queue-length=1
          operation=GetEventEnableCondition, queue-length=1
          operation=GetEventExtendedDataRecord, queue-length=1
          operation=GetEventFailed, queue-length=1
          operation=GetEventFreezeFrameData, queue-length=1
          operation=GetEventStatus, queue-length=1
          operation=GetEventTested, queue-length=1
          operation=GetFaultDetectionCounter, queue-length=1
      EvtInfo_SysThermErrTHi: provided-interface=DiagnosticInfo
        provided-com-specs:
          operation=GetDebouncingOfEvent, queue-length=1
          operation=GetDTCOfEvent, queue-length=1
          operation=GetEventEnableCondition, queue-length=1
          operation=GetEventExtendedDataRecord, queue-length=1
          operation=GetEventFailed, queue-length=1
          operation=GetEventFreezeFrameData, queue-length=1
          operation=GetEventStatus, queue-length=1
          operation=GetEventTested, queue-length=1
          operation=GetFaultDetectionCounter, queue-length=1
      EvtInfo_WDG_59_DRIVERA_E_INT_INCONSISTENT: provided-interface=DiagnosticInfo
        provided-com-specs:
          operation=GetDebouncingOfEvent, queue-length=1
          operation=GetDTCOfEvent, queue-length=1
          operation=GetEventEnableCondition, queue-length=1
          operation=GetEventExtendedDataRecord, queue-length=1
          operation=GetEventFailed, queue-length=1
          operation=GetEventFreezeFrameData, queue-length=1
          operation=GetEventStatus, queue-length=1
          operation=GetEventTested, queue-length=1
          operation=GetFaultDetectionCounter, queue-length=1
      EvtInfo_WDG_E_DISABLE_REJECTED: provided-interface=DiagnosticInfo
        provided-com-specs:
          operation=GetDebouncingOfEvent, queue-length=1
          operation=GetDTCOfEvent, queue-length=1
          operation=GetEventEnableCondition, queue-length=1
          operation=GetEventExtendedDataRecord, queue-length=1
          operation=GetEventFailed, queue-length=1
          operation=GetEventFreezeFrameData, queue-length=1
          operation=GetEventStatus, queue-length=1
          operation=GetEventTested, queue-length=1
          operation=GetFaultDetectionCounter, queue-length=1
      EvtInfo_WDG_E_MODE_FAILED: provided-interface=DiagnosticInfo
        provided-com-specs:
          operation=GetDebouncingOfEvent, queue-length=1
          operation=GetDTCOfEvent, queue-length=1
          operation=GetEventEnableCondition, queue-length=1
          operation=GetEventExtendedDataRecord, queue-length=1
          operation=GetEventFailed, queue-length=1
          operation=GetEventFreezeFrameData, queue-length=1
          operation=GetEventStatus, queue-length=1
          operation=GetEventTested, queue-length=1
          operation=GetFaultDetectionCounter, queue-length=1
      EvtInfo_WDG_E_READBACK_FAILURE: provided-interface=DiagnosticInfo
        provided-com-specs:
          operation=GetDebouncingOfEvent, queue-length=1
          operation=GetDTCOfEvent, queue-length=1
          operation=GetEventEnableCondition, queue-length=1
          operation=GetEventExtendedDataRecord, queue-length=1
          operation=GetEventFailed, queue-length=1
          operation=GetEventFreezeFrameData, queue-length=1
          operation=GetEventStatus, queue-length=1
          operation=GetEventTested, queue-length=1
          operation=GetFaultDetectionCounter, queue-length=1
      EvtInfo_Wdg_E_REG_WRITE_VERIFY: provided-interface=DiagnosticInfo
        provided-com-specs:
          operation=GetDebouncingOfEvent, queue-length=1
          operation=GetDTCOfEvent, queue-length=1
          operation=GetEventEnableCondition, queue-length=1
          operation=GetEventExtendedDataRecord, queue-length=1
          operation=GetEventFailed, queue-length=1
          operation=GetEventFreezeFrameData, queue-length=1
          operation=GetEventStatus, queue-length=1
          operation=GetEventTested, queue-length=1
          operation=GetFaultDetectionCounter, queue-length=1
      EvtInfo_WDG_E_TRIGGER_TIMEOUT: provided-interface=DiagnosticInfo
        provided-com-specs:
          operation=GetDebouncingOfEvent, queue-length=1
          operation=GetDTCOfEvent, queue-length=1
          operation=GetEventEnableCondition, queue-length=1
          operation=GetEventExtendedDataRecord, queue-length=1
          operation=GetEventFailed, queue-length=1
          operation=GetEventFreezeFrameData, queue-length=1
          operation=GetEventStatus, queue-length=1
          operation=GetEventTested, queue-length=1
          operation=GetFaultDetectionCounter, queue-length=1
      GeneralEventInfo: provided-interface=GeneralDiagnosticInfo
        provided-com-specs:
          operation=GetDebouncingOfEvent, queue-length=1
          operation=GetDTCOfEvent, queue-length=1
          operation=GetEventEnableCondition, queue-length=1
          operation=GetEventExtendedDataRecord, queue-length=1
          operation=GetEventFailed, queue-length=1
          operation=GetEventFreezeFrameData, queue-length=1
          operation=GetEventStatus, queue-length=1
          operation=GetEventTested, queue-length=1
          operation=GetFaultDetectionCounter, queue-length=1
      IndStatus_PwrSteerIndcr: server-com-spec{operation=GetIndicatorStatus, queue-length=1}, provided-interface=IndicatorStatus
      IndStatus_SteerAssiLimd: server-com-spec{operation=GetIndicatorStatus, queue-length=1}, provided-interface=IndicatorStatus
      IndStatus_SteerAssiLimdLvl2: server-com-spec{operation=GetIndicatorStatus, queue-length=1}, provided-interface=IndicatorStatus
      IndStatus_SteerAssiLimdLvl3: server-com-spec{operation=GetIndicatorStatus, queue-length=1}, provided-interface=IndicatorStatus
      OpCycle_PowerCycle: server-com-spec{operation=SetOperationCycleState, queue-length=1}, provided-interface=OperationCycle
      OverflowIndPrimaryMemory: provided-interface=EvMemOverflowIndication
        provided-com-specs:
          operation=GetEventMemoryOverflow, queue-length=1
          operation=GetNumberOfEventMemoryEntries, queue-length=1
    20 x require port:
      CBReadData_BattVltgEcu: required-interface=CSDataServices_BattVltgEcu
      CBReadData_EcuIntT: required-interface=CSDataServices_EcuIntT
      CBReadData_EngSpd: required-interface=CSDataServices_EngSpd
      CBReadData_EpdMotOvldProtnCntr: required-interface=CSDataServices_EpdMotOvldProtnCntr
      CBReadData_EpsAgOvrlSts: required-interface=CSDataServices_EpsAgOvrlSts
      CBReadData_EpsApaAgOvrlReq: required-interface=CSDataServices_EpsApaAgOvrlReq
      CBReadData_EpsMotCurr: required-interface=CSDataServices_EpsMotCurr
      CBReadData_EpsMotCurrFb: required-interface=CSDataServices_EpsMotCurrFb
      CBReadData_EpsStopStrtSts: required-interface=CSDataServices_EpsStopStrtSts
      CBReadData_EpsTqOvrlReq: required-interface=CSDataServices_EpsTqOvrlReq
      CBReadData_EpsTqOvrlSts: required-interface=CSDataServices_EpsTqOvrlSts
      CBReadData_IgnCycCntr: required-interface=CSDataServices_IgnCycCntr
      CBReadData_SplrIntDtcInfo: required-interface=CSDataServices_SplrIntDtcInfo
      CBReadData_SteerInpTq: required-interface=CSDataServices_SteerInpTq
      CBReadData_SteerOutpTq: required-interface=CSDataServices_SteerOutpTq
      CBReadData_SteerWhlAg: required-interface=CSDataServices_SteerWhlAg
      CBReadData_SysPwrMod: required-interface=CSDataServices_SysPwrMod
      CBReadData_TiIgnOn: required-interface=CSDataServices_TiIgnOn
      CBReadData_VehSpd: required-interface=CSDataServices_VehSpd
      CBStatusDTC_1: required-interface=CallbackDTCStatusChange
    behavior DemInternalBehavior: included-data-type-set=data-type=[Dem_DebounceResetStatusType, Dem_DebouncingStateType, Dem_DTCFormatType, Dem_DTCGroupType, Dem_DTCKindType, Dem_DTCStatusMaskType, Dem_EventIdType, Dem_EventStatusExtendedType, Dem_EventStatusType, Dem_IndicatorStatusType, Dem_InitMonitorReasonType, Dem_IumprDenomCondIdType, Dem_IumprDenomCondStatusType, Dem_MaxDataValueType, Dem_OperationCycleStateType, Dem_RatioIdType]
      6 x operation invoked event:
        OpEventClearDTC_ClearDTC_Cdd: start-on-event=ClearDTC, operation=Cdd.ClearDTC
        OpEventDcmClearDTC_DcmClearDTC_Dcm: start-on-event=DcmClearDTC, operation=Dcm.DcmClearDTC
        OpEventDcmEnableDTCSetting_DcmEnableDTCSetting_Dcm: start-on-event=DcmEnableDTCSetting, operation=Dcm.DcmEnableDTCSetting
        OpEventDcmGetExtendedDataRecordByDTC_DcmGetExtendedDataRecordByDTC_Dcm: start-on-event=DcmGetExtendedDataRecordByDTC, operation=Dcm.DcmGetExtendedDataRecordByDTC
        OpEventDcmGetFreezeFrameDataByDTC_DcmGetFreezeFrameDataByDTC_Dcm: start-on-event=DcmGetFreezeFrameDataByDTC, operation=Dcm.DcmGetFreezeFrameDataByDTC
        OpEventDcmGetNextFilteredDTCAndFDC_DcmGetNextFilteredDTCAndFDC_Dcm: start-on-event=DcmGetNextFilteredDTCAndFDC, operation=Dcm.DcmGetNextFilteredDTCAndFDC
      timing event Timer_Dem_MainFunction: start-on-event=Dem_MainFunction, period=0.01
